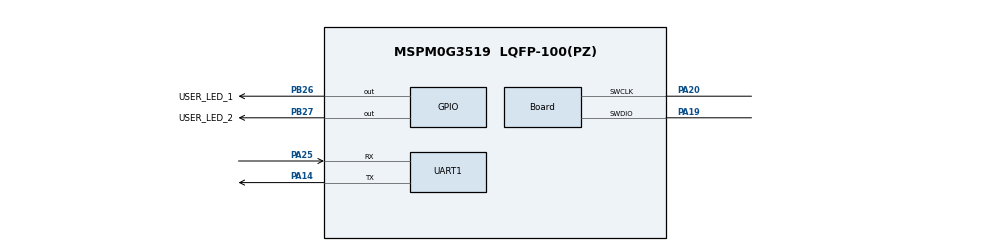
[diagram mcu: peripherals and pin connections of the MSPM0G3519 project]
//@cliArgs --device "MSPM0G351X" --package "LQFP-100(PZ)" --part "Default"
//@v2CliArgs --device "MSPM0G3519" --package "LQFP-100(PZ)"
// @cliArgs --board /ti/boards/LP_MSPM0G3519 --rtos nortos

/**
 * Import the modules used in this configuration.
 */
const GPIO   = scripting.addModule("/ti/driverlib/GPIO", {}, false);
const GPIO1  = GPIO.addInstance();
const GPIO2  = GPIO.addInstance();
const SYSCTL = scripting.addModule("/ti/driverlib/SYSCTL");
const UART   = scripting.addModule("/ti/driverlib/UART", {}, false);
const UART1  = UART.addInstance();

/**
 * Write custom configuration values to the imported modules.
 */
GPIO1.$name                         = "GPIO_LEDS";
GPIO1.associatedPins.create(2);
GPIO1.associatedPins[0].$name       = "USER_LED_1";
GPIO1.associatedPins[0].pin.$assign = "PB26";
GPIO1.associatedPins[1].$name       = "USER_LED_2";
GPIO1.associatedPins[1].pin.$assign = "PB27";

const Board                       = scripting.addModule("/ti/driverlib/Board", {}, false);
Board.peripheral.$assign          = "DEBUGSS";
Board.peripheral.swclkPin.$assign = "PA20";
Board.peripheral.swdioPin.$assign = "PA19";

GPIO2.$name                              = "GPIO_SWITCHES";
GPIO2.associatedPins[0].$name            = "USER_SWITCH_1";
GPIO2.associatedPins[0].direction        = "INPUT";
GPIO2.associatedPins[0].internalResistor = "PULL_UP";
GPIO2.associatedPins[0].interruptEn      = true;
GPIO2.associatedPins[0].polarity         = "FALL";
GPIO2.associatedPins[0].assignedPort     = "PORTB";
GPIO2.associatedPins[0].assignedPin      = "3";

SYSCTL.powerPolicy           = "STANDBY0";
SYSCTL.forceDefaultClkConfig = true;
SYSCTL.clockTreeEn           = true;

UART1.$name                    = "UART_0";
UART1.rxFifoThreshold          = "DL_UART_RX_FIFO_LEVEL_ONE_ENTRY";
UART1.enableDMARX              = false;
UART1.enableDMATX              = false;
UART1.uartClkSrc               = "LFCLK";
UART1.ovsRate                  = "3";
UART1.enabledInterrupts        = ["RX"];
UART1.enableInternalLoopback   = true;
UART1.peripheral.$assign       = "UART3";
UART1.peripheral.rxPin.$assign = "PA25";
UART1.peripheral.txPin.$assign = "PA14";

const ProjectConfig              = scripting.addModule("/ti/project_config/ProjectConfig", {}, false);
ProjectConfig.migrationCondition = true;
